# USB0_COMMON_0_VBP2APB_WRAP_CONTROLLER_VBP_CORE_ADDR_MAP register map
Vendor: Texas Instruments
Registers are 32-bit, access per field, reset 0x0 unless marked. A register's access mark holds for its fields unless they carry their own. Offsets are as the file gives them; [hi:lo] are bit positions; {n}, {i} and the like mark numbered series.

## USB0_COMMON_0_VBP2APB_WRAP_CONTROLLER_VBP_CORE_ADDR_MAP (part 4 of 8)
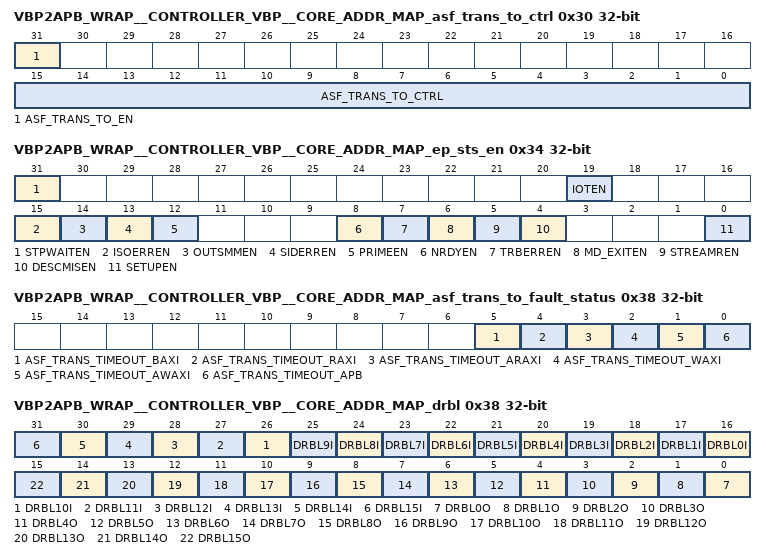
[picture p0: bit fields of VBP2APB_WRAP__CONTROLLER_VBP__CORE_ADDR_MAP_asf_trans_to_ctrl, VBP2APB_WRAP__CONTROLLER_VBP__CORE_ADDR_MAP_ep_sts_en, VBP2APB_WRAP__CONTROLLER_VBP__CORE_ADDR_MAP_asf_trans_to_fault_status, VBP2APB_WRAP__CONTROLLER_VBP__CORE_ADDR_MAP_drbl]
0x30 VBP2APB_WRAP__CONTROLLER_VBP__CORE_ADDR_MAP_asf_trans_to_ctrl
  [31] ASF_TRANS_TO_EN rw — Enable transaction timeout monitoring.
  [15:0] ASF_TRANS_TO_CTRL rw — Timer value to use for transaction timeout monitor.
0x30 VBP2APB_WRAP__CONTROLLER_VBP__CORE_ADDR_MAP_ep_sts_sid ro
  [15:0] SID — Stream ID [used only in SS mode]. Stream ID of packet, which generates interrupt. The interrupts that update the SID field are: - SIDERR for EP OUT - SIDERR/DESCMIS for EP IN For the above interrupts, the values of the SID field reflects: - in case of SIDERR for EP OUT this field reflects the Stream ID of OUT packet sent by host which was rejected by the device, due to SID_CHK bit set - in case of SIDERR/DESCMIS for EP IN this field reflects the Stream ID of ACK TP sent by host which was rejected by the device.
0x34 VBP2APB_WRAP__CONTROLLER_VBP__CORE_ADDR_MAP_asf_trans_to_fault_mask rw reset 0xFFFFFFFF
  [31:0] ASF_TRANS_TO_FAULT_MASK — Mask register for each ASF transaction timeout fault source.
0x34 VBP2APB_WRAP__CONTROLLER_VBP__CORE_ADDR_MAP_ep_sts_en
  [31] STPWAITEN rw — Setup Wait interrupt enable. This bit enables the STPWAIT interrupt. Valid only for EP0
  [19] IOTEN rw — Interrupt on Transmission complete enable. This bit enables the IOT interrupt.
  [15] ISOERREN rw — ISO transmission error enable. This bit enables the ISOERR interrupt.
  [14] OUTSMMEN rw — OUT size mismatch enable. This bit enables the OUTSMM interrupt.
  [13] SIDERREN rw — Stream error enable. This bit enables the SIDERR interrupt.
  [12] PRIMEEN rw — Prime enable. This bit enables the PRIME interrupt.
  [8] NRDYEN rw — NRDY enable. This bit enables the NRDY interrupt.
  [7] TRBERREN rw — TRB enable. This bit enables the TRBERR interrupt.
  [6] MD_EXITEN rw — Move Data Exit enable. This bit enables the MD_EXIT interrupt.
  [5] STREAMREN rw — Stream Rejected enable. This bit enables the STREAMR interrupt.
  [4] DESCMISEN rw — OUT transfer missing descriptor enable. This bit enables the DESCMIS interrupt.
  [0] SETUPEN rw — Setup transfer complete. This bit enables the SETUP interrupt. Valid only for EP0.
0x38 VBP2APB_WRAP__CONTROLLER_VBP__CORE_ADDR_MAP_asf_trans_to_fault_status access not given
  [5] ASF_TRANS_TIMEOUT_BAXI — Status bits for transaction timeouts faults - AXI Timeout [BAXI] (access R/W1TC)
  [4] ASF_TRANS_TIMEOUT_RAXI — Status bits for transaction timeouts faults - AXI Timeout [RAXI] (access R/W1TC)
  [3] ASF_TRANS_TIMEOUT_ARAXI — Status bits for transaction timeouts faults - AXI Timeout [ARAXI] (access R/W1TC)
  [2] ASF_TRANS_TIMEOUT_WAXI — Status bits for transaction timeouts faults - AXI Timeout [WAXI] (access R/W1TC)
  [1] ASF_TRANS_TIMEOUT_AWAXI — Status bits for transaction timeouts faults - AXI Timeout [AWAXI] (access R/W1TC)
  [0] ASF_TRANS_TIMEOUT_APB — Status bit for transaction timeout faults - APB timeout. (access R/W1TC)
0x38 VBP2APB_WRAP__CONTROLLER_VBP__CORE_ADDR_MAP_drbl access not given
  [n+16] DRBL{n}I (n=0..15) — Dorbel Bit - used for initiating transfers for selected Endpoint (access R/W1TS)
  [n] DRBL{n}O (n=0..15) — Dorbel Bit - used for initiating transfers for selected Endpoint (access R/W1TS)
0x3C VBP2APB_WRAP__CONTROLLER_VBP__CORE_ADDR_MAP_RSVD_16_ASF ro
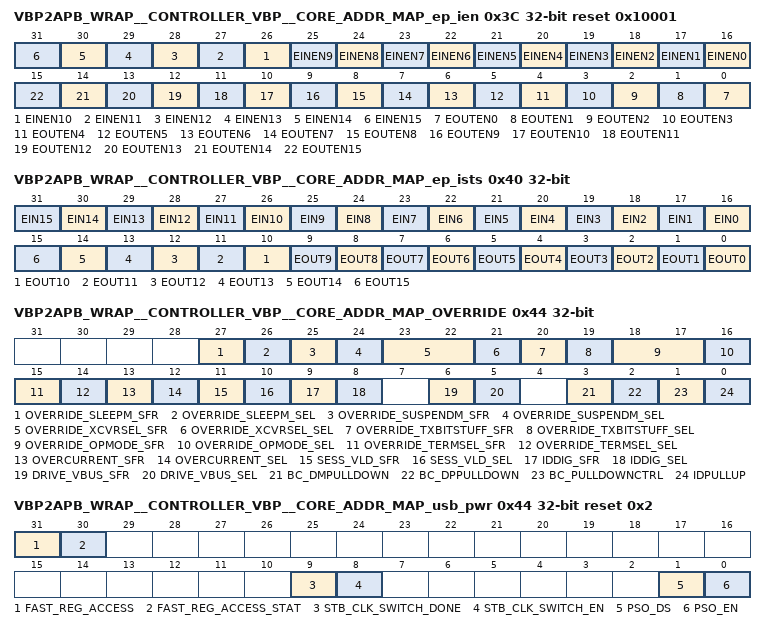
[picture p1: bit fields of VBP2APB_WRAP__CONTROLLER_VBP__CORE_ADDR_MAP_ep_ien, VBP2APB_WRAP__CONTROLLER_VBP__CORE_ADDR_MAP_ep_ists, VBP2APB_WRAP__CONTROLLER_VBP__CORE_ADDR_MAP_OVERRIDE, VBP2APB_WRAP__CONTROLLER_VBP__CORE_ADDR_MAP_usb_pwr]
0x3C VBP2APB_WRAP__CONTROLLER_VBP__CORE_ADDR_MAP_ep_ien rw reset 0x10001
  [n+16] EINEN{n} (n=0..15) — Endpoints Interrupt Enable Bit [1 - enables interrupt, 0 - disables interrupt]
  [n] EOUTEN{n} (n=0..15) — Endpoints Interrupt Enable Bit [1 - enables interrupt, 0 - disables interrupt]
0x40 VBP2APB_WRAP__CONTROLLER_VBP__CORE_ADDR_MAP_OTGSIMULATE
  [0] OTG_CFG_FAST_SIMS rw — Debug Feature. This bit is for simulation modes only. It enables reductions to OTG timings. '0': Normal timings '1': Enable fast simulation timing modes This bit should be written '0' in normal operation
0x40 VBP2APB_WRAP__CONTROLLER_VBP__CORE_ADDR_MAP_RSVD_17_ASF ro
0x40 VBP2APB_WRAP__CONTROLLER_VBP__CORE_ADDR_MAP_ep_ists ro
  [n+16] EIN{n} (n=0..15) — Endpoints Interrupt Status Bit.
  [n] EOUT{n} (n=0..15) — Endpoints Interrupt Status Bit.
0x44 VBP2APB_WRAP__CONTROLLER_VBP__CORE_ADDR_MAP_OVERRIDE
  [27] OVERRIDE_SLEEPM_SFR rw — SFR sleepm control. Value this bit is passed to PHY sleepm signal. This bit is valid only with PORT_OVERRIDE. override_sleepm_sel set to '1'.
  [26] OVERRIDE_SLEEPM_SEL rw — sleepm override select. This register allows SW driver override sleepm pin as follows: 0: sleepm is controlled from active controller [host/device/none] 1: sleepm controlled from SFR
  [25] OVERRIDE_SUSPENDM_SFR rw — SFR suspendm control. Value this bit is passed to PHY suspendm signal. This bit is valid only with PORT_OVERRIDE. override_suspendm_sel set to '1'.
  [24] OVERRIDE_SUSPENDM_SEL rw — suspendm override select. This register allows SW driver override suspendm pin as follows: 0: suspendm is controlled from active controller [host/device/none] 1: suspendm controlled from SFR
  [23:22] OVERRIDE_XCVRSEL_SFR rw — SFR xcvrselect control. Value of these bits is passed to PHY xcvrselect signal. This bit is valid only with PORT_OVERRRIDE. override_opmode_sel set to 1
  [21] OVERRIDE_XCVRSEL_SEL rw — xcvrselect override select. This register allows SW driver override xcvrselect pin as follows: 0: xcvrselect is controlled from active controller [host/device] 1: xcvrselect controlled from SFR
  [20] OVERRIDE_TXBITSTUFF_SFR rw — SFR txbitstuffenable control. Value this bit is passed to PHY txbitstuffenable signal. This bit is valid only with PORT_OVERRRIDE. override_txbitstuff_sel set to 1.
  [19] OVERRIDE_TXBITSTUFF_SEL rw — txbitstuffenable override select. This register allows SW driver override txbitstuffenable pin as follows: 0: txbitstuffenable is controlled from active controller [host/device] 1: txbitstuffenable controlled from SFR
  [18:17] OVERRIDE_OPMODE_SFR rw — SFR opmode control. Value these bits is passed to PHY opmode signal. This bit is valid only with PORT_OVERRRIDE. override_opmode_sel set to 1.
  [16] OVERRIDE_OPMODE_SEL rw — opmode override select. This register allows SW driver override opmode pin as follows: 0: opmode is controlled from active controller [host/device] 1: opmode controlled from SFR
  [15] OVERRIDE_TERMSEL_SFR rw — SFR overcurrent control. 0: overcurrent = 0 1: overcurrent = 1 This bit is valid only with PORT_OVERRRIDE.overcurrent_sel set to '1'. Note: overcurrent active state is low.
  [14] OVERRIDE_TERMSEL_SEL rw — termselect override select. This register allows SW driver override termselect pin as follows: 0: txbitstuffenable is controlled from active controller [host/device] 1: txbitstuffenable controlled from SFR
  [13] OVERCURRENT_SFR rw — SFR termselect control. Value this bit is passed to PHY termselect signal. This bit is valid only with PORT_OVERRRIDE. override_termsel_sel set to 1.
  [12] OVERCURRENT_SEL rw — Overcurrent override select This register allows SW driver override overcurrent pin as follows: 0: overcurrent is controlled from external FAULT detector 1: overcurrent controlled from SFR
  [11] SESS_VLD_SFR rw — SFR Vbusvalid/Sessvalid control. 0: Vbusvalid/Sessvalid = 0 1: Vbusvalid/Sessvalid = 1 This bit is valid only with PORT_OVERRRIDE.sess_vld_sel set to '1'.
  [10] SESS_VLD_SEL rw — Vbusvalid/Sessvalid override select. This register allows SW driver override Vbusvalid/Sessvalid pins as follows: 0: Vbusvalid/Sessvalid are controlled from OTG PHY 1: Vbusvalid/Sessvalid are controlled from SFR
  [9] IDDIG_SFR rw — SFR iddig control. 0: iddig = 0 1: iddig = 1 This bit is valid only with PORT_OVERRRIDE.iddig_sel set to '1'.
  [8] IDDIG_SEL rw — IDDIG override select. This register allows SW driver override iddig pin as follows: 0: iddig is controlled from OTG PHY 1: iddig controlled from SFR
  [6] DRIVE_VBUS_SFR rw — 0: drive_vbus = 0 1: drive_vbus = 1 This bit is valid only with USB2_PORT_OVERRRIDE.drive_vbus_sel set to '1'. This bit is auto-cleared upon over-current condition. Over-current doesn't disable vbus forcing.
  [5] DRIVE_VBUS_SEL rw — This register allows SW driver take control over drive_vbus as follows: 0: drive_vbus controlled from OTG controller 1: drive_vbus controlled from SFR
  [3] BC_DMPULLDOWN rw — dmpulldown enable This bit is valid only with PORT_OVERRRIDE.pulldownctrl_sel set to 1
  [2] BC_DPPULLDOWN rw — BC dppulldown enable This bit is valid only with PORT_OVERRRIDE.pulldownctrl_sel set to 1
  [1] BC_PULLDOWNCTRL rw — pulldowncotrol 1: puldowns are controlled by dppulldown_sfr and dmpulldown_sfr 0: puldowns are controlled by OTG
  [0] IDPULLUP rw — ID Pin Sample Enable: Active High. Signal that enables the sampling of the analog ID line. 0: Sampling of ID pin is disabled, iddig is not valid 1: Sampling of ID pin is enabled
0x44 VBP2APB_WRAP__CONTROLLER_VBP__CORE_ADDR_MAP_RSVD_18_ASF ro
0x44 VBP2APB_WRAP__CONTROLLER_VBP__CORE_ADDR_MAP_usb_pwr access not given reset 0x2
  [31] FAST_REG_ACCESS rw — Fast Registers Access. When Device Port is in a low power state [U3/L2/Not Connected], accesses to registers listed in section 2.3 of USBSS-DEV design specification may take long time. In order to enable fast register access in that case, user can use this register in the following way: - set FAST_REG_ACCESS bit - wait until FAST_REG_ACCESS_STAT bit is set - perform required accesses - clear FAST_REG_ACCESS bit Note that to enable USBSS-DEV low power state entry [U3/L2], the FAST_REG_ACCESS bit has to be cleared.
  [30] FAST_REG_ACCESS_STAT ro — Fast Registers Access status. This bit informs if Fast Registers Access is enabled. It should be used as described in FAST_REG_ACCESS bit.
  [9] STB_CLK_SWITCH_DONE ro — Status bit indicating that operation required by STB_CLK_SWITCH_EN write is completed. This bit is optional and implemented only when support for OTG is implemented [indicated by OTG_READY bit set to 1].
  [8] STB_CLK_SWITCH_EN rw — Enables turning-off Reference Clock. This bit is optional and implemented only when support for OTG is implemented [indicated by OTG_READY bit set to 1]. Should not be used when PHY Reference clock control is not supported
  [1] PSO_DS — Power Shut Off capability disable. Writing '1' to this bit disables power domains switching capability and clears the PSO_EN bit. It is recommended to set this bit after during U3EXTI interrupt service. (access R/W1TS)
  [0] PSO_EN — Power Shut Off capability enable. Writing '1' to this bit enables dower domains switching capability and clears the PSO_DS bit. The Domain will be switched off if both PSO_EN will be set and the USB controller will be in the in the U3 state. It is recommended to set this bit in U3ENTI interrupt service, after software ensures that no data transfer is pending. If this bit will be always set, the controller will automatically switch off the power in the switchable PD after USB controller will enter U3 state. (access R/W1TC)
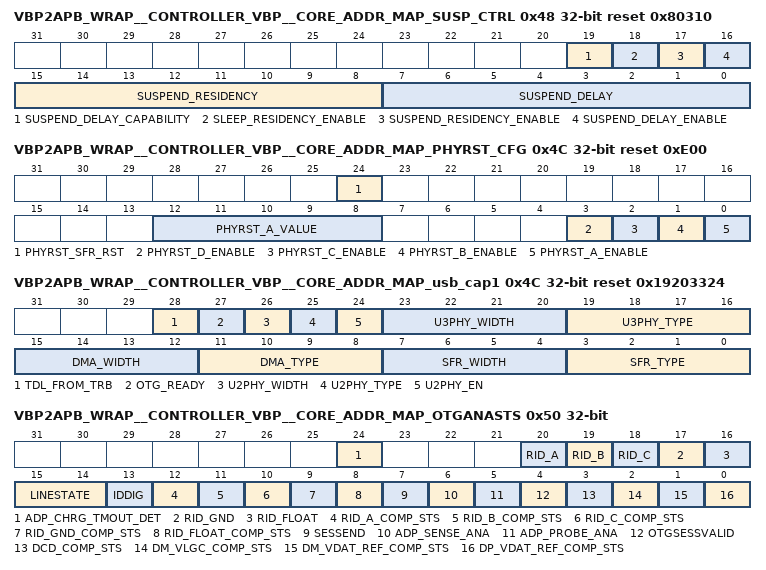
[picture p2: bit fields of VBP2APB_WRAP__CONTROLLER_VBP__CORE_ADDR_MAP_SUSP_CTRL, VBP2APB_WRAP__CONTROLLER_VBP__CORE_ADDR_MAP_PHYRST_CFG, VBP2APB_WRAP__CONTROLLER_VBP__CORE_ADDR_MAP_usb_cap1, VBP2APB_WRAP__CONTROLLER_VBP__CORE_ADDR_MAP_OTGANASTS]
0x48 VBP2APB_WRAP__CONTROLLER_VBP__CORE_ADDR_MAP_SUSP_CTRL reset 0x80310
  [19] SUSPEND_DELAY_CAPABILITY ro — Suspend delay capability. This is a configuration only field, therefore it can be changed by Software only during configuration phase when Power-On Reset [pwrup_rst_n] is asserted.
  [18] SLEEP_RESIDENCY_ENABLE rw — sleep minimum residency enable. This is a configuration only field, therefore it can be changed by Software only during configuration phase when Power-On Reset [pwrup_rst_n] is asserted.
  [17] SUSPEND_RESIDENCY_ENABLE rw — suspend minimum residency enable. This is a configuration only field, therefore it can be changed by Software only during configuration phase when Power-On Reset [pwrup_rst_n] is asserted.
  [16] SUSPEND_DELAY_ENABLE rw — suspend delay enable. This is a configuration only field, therefore it can be changed by Software only during configuration phase when Power-On Reset [pwrup_rst_n] is asserted.
  [15:8] SUSPEND_RESIDENCY rw — Suspend/Sleep minimum residency time [us]. This is a configuration only field, therefore it can be changed by Software only during configuration phase when Power-On Reset [pwrup_rst_n] is asserted.
  [7:0] SUSPEND_DELAY rw — Suspend assertion delay time [us]. This is a configuration only field, therefore it can be changed by Software only during configuration phase when Power-On Reset [pwrup_rst_n] is asserted.
0x48 VBP2APB_WRAP__CONTROLLER_VBP__CORE_ADDR_MAP_usb_conf2
  [0] AHB_RETRY_EN rw — AHB retry enable. This bit enables the AHB retrys for AHB slave interface. This bit has no effect when AHB slave interface is not implemented.
0x4C VBP2APB_WRAP__CONTROLLER_VBP__CORE_ADDR_MAP_PHYRST_CFG reset 0xE00
  [24] PHYRST_SFR_RST rw — Software USB20 PHy reset: 0 - SW utmi_reset not asserted 1 - SW utmi_reset asserted
  [12:8] PHYRST_A_VALUE rw — phyrst_a Rx fail timeout value. Value of this register is used as a timeout value for detecting Rx fail [utmi_rxactive is not up during Rx] Value of this register represent maximum number of UTMI clock cycles where utmi_rxactive is expected to rise with respect to Rx start judged by non-idle state utmi_linestate
  [3] PHYRST_D_ENABLE rw — Reset PHY after each utmi_opmode change from 2'b10 to any other value: 0 - disabled 1 - enabled
  [2] PHYRST_C_ENABLE rw — Reset PHY after each utmi_opmode change from 2'b01 to any other value: 0 - disabled 1 - enabled
  [1] PHYRST_B_ENABLE rw — Reset PHY after each transmitted packet in High-Speed: 0 - disabled 1 - enabled
  [0] PHYRST_A_ENABLE rw — Reset PHY if Rx fail is detected: 0 - disabled 1 - enabled
0x4C VBP2APB_WRAP__CONTROLLER_VBP__CORE_ADDR_MAP_usb_cap1 ro reset 0x19203324
  [28] TDL_FROM_TRB — This field informs if device controller supports automatic internal TDL calculation basing on the size provided in TRB for DMULT mode: - 0 - controller doesn't support automatic internal TDL calculation - 1 - controller supports automatic internal TDL calculation
  [27] OTG_READY — This field informs if device is OTG ready: - pure device mode: 0x0, - some features and ports for CDNS USB OTG controller are implemented: 0x1.
  [26] U2PHY_WIDTH — USB2 PHY Interface width. This field reflects width of USB2 PHY interface implemented: - 8 bit interface: 0x0, - 16 bit interface: 0x1. Note: The ULPI interface is always 8-bit wide.
  [25] U2PHY_TYPE — USB2 PHY Interface type. This field reflects type of USB2 PHY interface implemented: - UTMI: 0x0, - ULPI: 0x1.
  [24] U2PHY_EN — USB2 PHY Interface enable. This field informs if USB2 PHY interface is implemented: - interface NOT implemented: 0x0, - interface implemented: 0x1.
  [23:20] U3PHY_WIDTH — USB3 PHY Interface width. This field reflects width of USB3 PHY interface implemented: - 0x0: 8 bit PIPE interface, - 0x1: 16 bit PIPE interface, - 0x2: 32 bit PIPE interface, - 0x3: 64 bit PIPE interface, - 0x4-0xF: reserved. Note: When SSIC interface is implemented this field shows the width of internal PIPE interface. The RMMI interface is always 20-bit wide.
  [19:16] U3PHY_TYPE — USB3 PHY Interface type. This field reflects type of USB3 PHY interface implemented: - 0x0: USB PIPE, - 0x1: RMMI, - 0x2-0xF: reserved
  [15:12] DMA_WIDTH — DMA Interface width. This field reflects width of DMA interface implemented: - 0x0: reserved, - 0x1: reserved, - 0x2: 32 bit interface, - 0x3: 64 bit interface, - 0x4-0xF: reserved
  [11:8] DMA_TYPE — DMA Interface type. This field reflects type of DMA interface implemented: - 0x0: OCP, - 0x1: AHB, - 0x2: PLB, - 0x3: AXI, - 0x4-0xF: reserved
  [7:4] SFR_WIDTH — SFR Interface width. This field reflects width of SFR interface implemented: - 0x0: 8 bit interface, - 0x1: 16 bit interface, - 0x2: 32 bit interface, - 0x3: 64 bit interface, - 0x4-0xF: reserved
  [3:0] SFR_TYPE — SFR Interface type. This field reflects type of SFR interface implemented: 0x0 - OCP, 0x1 - AHB, 0x2 - PLB, 0x3 - AXI, 0x4 - APB, 0x5-0xF - reserved.
0x50 VBP2APB_WRAP__CONTROLLER_VBP__CORE_ADDR_MAP_OTGANASTS ro
  [24] ADP_CHRG_TMOUT_DET — ADP charge timeout detected
  [20] RID_A — RID A status reg
  [19] RID_B — RID B status reg
  [18] RID_C — RID C status reg
  [17] RID_GND — RID GND status reg
  [16] RID_FLOAT — RID float status reg
  [15:14] LINESTATE — Line State: These signals reflect the current state of the single ended receivers. They are combinatorial until a 'usable' sieclock is available, then they are synchronized to sieclock. They reflect the current state of the DP [linestate [0]] and DM [linestate [1]] signals. 00: SE0 [Single Ended Zero] 01: 'J' State 10: 'K' State 11: SE1 [Single Ended One]
  [13] IDDIG — ID Pin Status: Indicates whether the connected USB plug is Micro-A or Micro-B. This is only valid when idpullup is set to '1'. It must be valid within 50ms after idpullup is set to '1'. 0: Connected plug is a Micro-A 1: Connected plug is a Micro-B
  [12] RID_A_COMP_STS — RID A comparator status 1: RID_A Detected on ID Pin 0: RID_A not Detected on ID Pin
  [11] RID_B_COMP_STS — RID B comparator status 1: RID_B Detected on ID Pin 0: RID_B not Detected on ID Pin
  [10] RID_C_COMP_STS — RID C comparator status 1: RID_C Detected on ID Pin 0: RID_C not Detected on ID Pin
  [9] RID_GND_COMP_STS — RID GND comparator status 1: RID_GND Detected on ID Pin 0: RID_GND not Detected on ID Pin
  [8] RID_FLOAT_COMP_STS — RID float comparator status 1: RID_FLOAT Detected on ID Pin 0: RID_FLOAT not Detected on ID Pin
  [7] SESSEND — VBUS Valid: Indicates if the voltage on VBUS is at a valid level for operation [4.4V less than VTH less than 4.75V]. 0: VBUS less than 4.4V 1: VBUS > 4.75V
  [6] ADP_SENSE_ANA — Output of ADP Sense Comparator. 0: VBUS less than 0.2V 1: VBUS > 0.55V
  [5] ADP_PROBE_ANA — Output of ADP Probe Comparator. 0: VBUS less than 0.6V 1: VBUS > 0.75V
  [4] OTGSESSVALID — B-Peripheral is Valid: Indicates if the session for a B-Peripheral is valid [0.8V less than VTH less than 4.0V]. The signal bvalid from OTG 1.3 is now renamed as otgsessvalid. 0: VBUS less than 0.8V 1: VBUS > 4.0V
  [3] DCD_COMP_STS — Data Contact Detect [DCD] Comparator Status 1: DP line is asserted 0: DP line is not asserted
  [2] DM_VLGC_COMP_STS — 1: DM > VLGC Detected 0: DM less than VLGC Detected Note: This status shall be re-used from the single ended receiver output of D- whenever dm_vlgc_comp_en is '1'.
  [1] DM_VDAT_REF_COMP_STS — 1: DM > VDAT_REF Detected 0: DM less than VDAT_REF Detected Note: This status shall be re-used from the single ended receiver output of D- whenever dm_vdat_ref_comp_en is '1'.
  [0] DP_VDAT_REF_COMP_STS — 1: DP > VDAT_REF Detected 0: DP less than VDAT_REF Detected Note: This status shall be re-used from the single ended receiver output of D+ whenever dp_vdat_ref_comp_en is '1'.
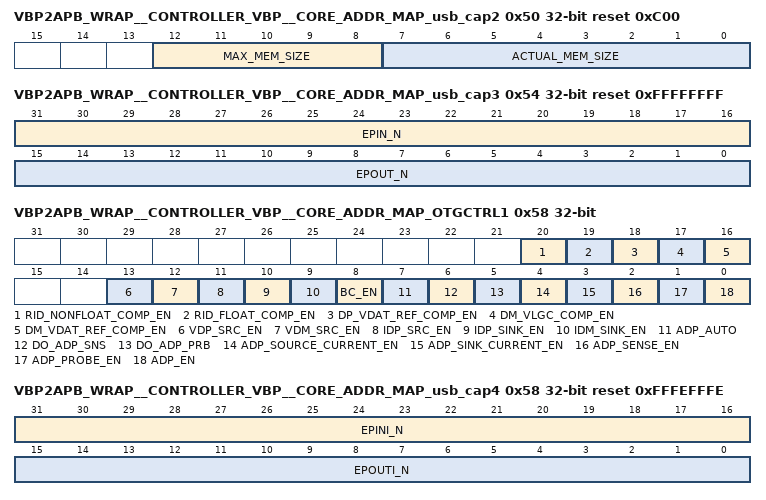
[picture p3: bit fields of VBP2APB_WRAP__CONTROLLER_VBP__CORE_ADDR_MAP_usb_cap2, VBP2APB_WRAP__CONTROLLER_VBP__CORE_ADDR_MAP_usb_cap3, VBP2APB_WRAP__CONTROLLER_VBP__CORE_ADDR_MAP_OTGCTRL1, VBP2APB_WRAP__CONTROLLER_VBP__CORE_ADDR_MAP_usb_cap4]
0x50 VBP2APB_WRAP__CONTROLLER_VBP__CORE_ADDR_MAP_usb_cap2 ro reset 0xC00
  [12:8] MAX_MEM_SIZE — Max supported mem size. This field reflects width of on-chip RAM address bus width, which determines max supported mem size: 0x0-0x7 reserved, 0x8 - support for 4kB mem, 0x9 - support for 8kB mem, 0xA - support for 16kB mem, 0xB - support for 32kB mem, 0xC - support for 64kB mem, 0xD - support for 128kB mem, 0xE - support for 256kB mem, 0xF - reserved.
  [7:0] ACTUAL_MEM_SIZE — The actual size of the connected On-chip RAM memory in kB: - 0 means 256 kB [max supported mem size] - value other than 0 reflects the mem size in kB. This value reflects the CDNS_USBSSDEV_ATTACHED_MEM_SIZE parameter defined in the usbss_dev_defines.v file. This value has to be adequately set before synthesis by engineer who connects the on-chip memory for controller.
0x54 VBP2APB_WRAP__CONTROLLER_VBP__CORE_ADDR_MAP_ADP_RAMP_TIME ro
  [31:0] ADP_RAMP_TIME — ADP ramp time measurement value. Software should read this register upon ADP_PROBE_COMPLETED_INT_EN interrupt detection
0x54 VBP2APB_WRAP__CONTROLLER_VBP__CORE_ADDR_MAP_usb_cap3 ro reset 0xFFFFFFFF
  [31:16] EPIN_N — Endpoints IN
  [15:0] EPOUT_N — Endpoints OUT
0x58 VBP2APB_WRAP__CONTROLLER_VBP__CORE_ADDR_MAP_OTGCTRL1
  [20] RID_NONFLOAT_COMP_EN rw — 1: RID Non-Float Comparator Enabled 0: RID Non-Float Comparator Disabled Note: This ID Comparator enable is used to detect the presence of RID_A or RID_B or RID_C or RID_GND when the ID pin is non-floating.
  [19] RID_FLOAT_COMP_EN rw — 1: RID Float Comparator Enabled 0: RID Float Comparator Disabled Note: This ID Comparator enable is used to detect whether the ID line is floating or non-floating. If it is identified to be non-floating, then rid_nonfloat_comp_en is enabled to check for RID_A or RID_B or RID_C or RID_GND.
  [18] DP_VDAT_REF_COMP_EN rw — 1: DP to VDAT_REF Comparator Enabled 0: DP to VDAT_REF Comparator Disabled
  [17] DM_VLGC_COMP_EN rw — 1: DM to VLGC Comparator Enabled 0: DM to VLGC Comparator Disabled
  [16] DM_VDAT_REF_COMP_EN rw — 1: DM to VDAT_REF Comparator Enabled 0: DM to VDAT_REF Comparator Disabled
  [13] VDP_SRC_EN rw — 1: Voltage Source on DP Enabled 0: Voltage Source on DP Disabled
  [12] VDM_SRC_EN rw — 1: Voltage Source on DM Enabled 0: Voltage Source on DM Disabled
  [11] IDP_SRC_EN rw — 1: Current Source on DP Enabled 0: Current Source on DP Disabled
  [10] IDP_SINK_EN rw — 1: Current Sink on DP Enabled 0: Current Sink on DP Disabled
  [9] IDM_SINK_EN rw — 1: Current Sink on DM Enabled 0: Current Sink on DM Disabled
  [8] BC_EN rw — Battery Charging Circuits Master Enable. 1: BC Enabled 0: BC Disabled
  [7] ADP_AUTO rw — ADP mode. If set to 1 ADP probing is controlled by internal FSM. If set to 0 then software should control ADP sequence.
  [6] DO_ADP_SNS rw — ADP sensing enable in automated mode
  [5] DO_ADP_PRB rw — ADP probing enable in automated mode
  [4] ADP_SOURCE_CURRENT_EN rw — When this signal is high, VBUS is charged to the probe threshold [0.75V]. This signal should be asserted 5us after the assertion of adp_en. 0: ADP Source Current Enable OFF 1: ADP Source Current Enable ON
  [3] ADP_SINK_CURRENT_EN rw — When this signal is high, VBUS is discharged to ground. This signal should be asserted 5us after the assertion of adp_en. 0: ADP Sink Current Enable OFF 1: ADP Sink Current Enable ON
  [2] ADP_SENSE_EN rw — This signal enables the probe mode of the ADP. During this mode, sense comparators and the current sources will be ON based on the source and sink current enables. 0: ADP Probe Sense OFF 1: ADP Probe Sense ON
  [1] ADP_PROBE_EN rw — This signal enables the probe mode of the ADP. During this mode, probe comparators and the current sources will be ON based on the source and sink current enables. 0: ADP Probe Mode OFF 1: ADP Probe Mode ON
  [0] ADP_EN rw — ADP Feature Enable. This signal is the master enable for all the ADP PHY logics. 0: ADP Logics are powered OFF 1: ADP Logics are powered ON
0x58 VBP2APB_WRAP__CONTROLLER_VBP__CORE_ADDR_MAP_usb_cap4 ro reset 0xFFFEFFFE
  [31:16] EPINI_N — Endpoints IN
  [15:0] EPOUTI_N — Endpoints OUT
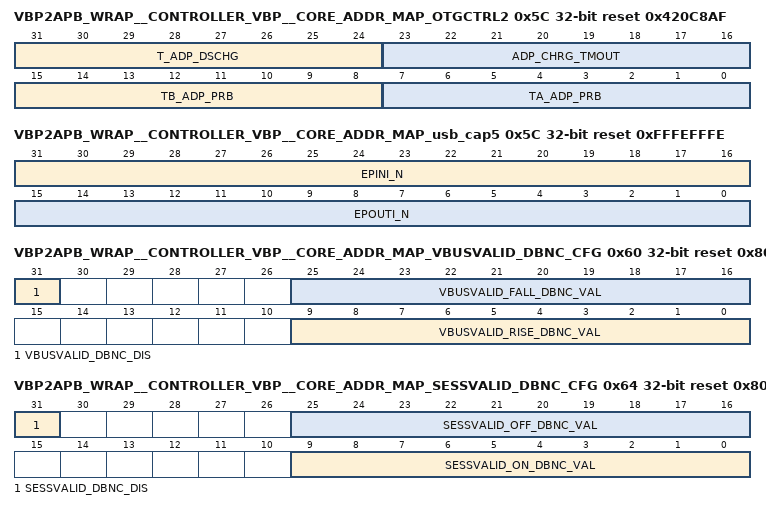
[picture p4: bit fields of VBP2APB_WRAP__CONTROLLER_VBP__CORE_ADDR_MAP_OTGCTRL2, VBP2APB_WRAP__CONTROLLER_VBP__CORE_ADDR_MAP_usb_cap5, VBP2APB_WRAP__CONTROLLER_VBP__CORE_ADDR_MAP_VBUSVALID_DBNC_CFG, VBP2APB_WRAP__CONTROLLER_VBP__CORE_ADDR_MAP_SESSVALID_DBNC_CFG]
0x5C VBP2APB_WRAP__CONTROLLER_VBP__CORE_ADDR_MAP_OTGCTRL2 rw reset 0x420C8AF
  [31:24] T_ADP_DSCHG — ADP probing discharge time. T_ADP_DSCHG = {reg_value} * 1 ms
  [23:16] ADP_CHRG_TMOUT — ADP probing timeout value. Defines maximum time for ADP charging. If this time is reached during charging then adp_chrg_tmout_det bit in OTGADPBCSTS is set ADP_CHRG_TMOUT = {reg_value} * 1 ms
  [15:8] TB_ADP_PRB — B-device ADP probing period. TB_ADP_PRB = {reg_value} * 10 ms
  [7:0] TA_ADP_PRB — A-device ADP probing period. TA_ADP_PRB = {reg_value} * 10 ms
0x5C VBP2APB_WRAP__CONTROLLER_VBP__CORE_ADDR_MAP_usb_cap5 ro reset 0xFFFEFFFE
  [31:16] EPINI_N — Endpoints IN
  [15:0] EPOUTI_N — Endpoints OUT
0x60 VBP2APB_WRAP__CONTROLLER_VBP__CORE_ADDR_MAP_VBUSVALID_DBNC_CFG reset 0x800A000A
  [31] VBUSVALID_DBNC_DIS rw — Vbusvalid debounce disable
  [25:16] VBUSVALID_FALL_DBNC_VAL rw — Vbusvalid off debounce: Debounce timer value = reg value x 100us
  [9:0] VBUSVALID_RISE_DBNC_VAL rw — Vbusvalid on debounce: Debounce timer value = reg value x 100us
0x60 VBP2APB_WRAP__CONTROLLER_VBP__CORE_ADDR_MAP_usb_cap6 ro reset 0x2450D
  [31:0] VERSION — Device controller version.
0x64 VBP2APB_WRAP__CONTROLLER_VBP__CORE_ADDR_MAP_SESSVALID_DBNC_CFG reset 0x800A0100
  [31] SESSVALID_DBNC_DIS rw — Sessvalid debounce disable
  [25:16] SESSVALID_OFF_DBNC_VAL rw — Sessvalid off debounce: Debounce timer value = reg value x 100us
  [9:0] SESSVALID_ON_DBNC_VAL rw — Sessvalid on debounce: Debounce timer value = reg value x 100us
{0x60+4i} VBP2APB_WRAP__CONTROLLER_VBP__CORE_ADDR_MAP_usb_cpkt{i} rw (i=1..3)
  [31:0] CPKT{i} — Custom Packet value {i}.
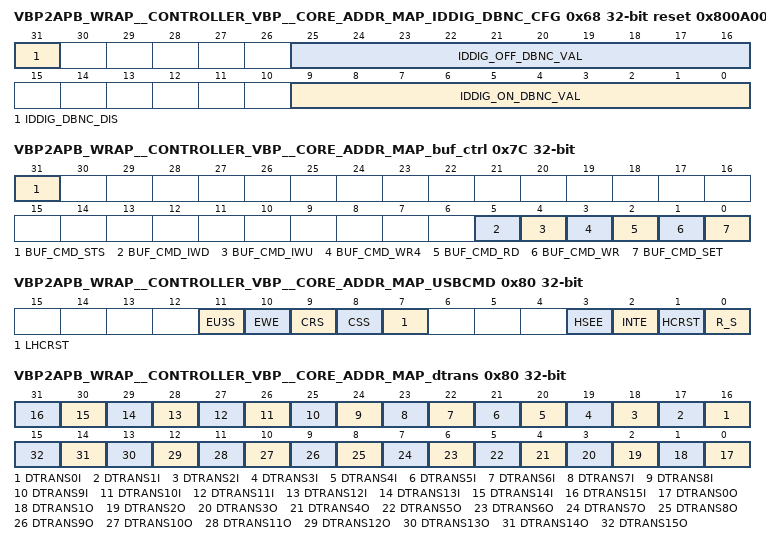
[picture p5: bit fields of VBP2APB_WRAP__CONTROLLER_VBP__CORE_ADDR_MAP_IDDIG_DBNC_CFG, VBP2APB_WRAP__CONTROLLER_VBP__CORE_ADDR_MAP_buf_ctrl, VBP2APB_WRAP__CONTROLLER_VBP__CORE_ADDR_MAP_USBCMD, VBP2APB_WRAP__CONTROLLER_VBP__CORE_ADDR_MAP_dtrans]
0x68 VBP2APB_WRAP__CONTROLLER_VBP__CORE_ADDR_MAP_IDDIG_DBNC_CFG reset 0x800A000A
  [31] IDDIG_DBNC_DIS rw — Iddig debounce disable
  [25:16] IDDIG_OFF_DBNC_VAL rw — Sessvalid off debounce: Debounce timer value = reg value x 100us
  [9:0] IDDIG_ON_DBNC_VAL rw — Sessvalid on debounce: Debounce timer value = reg value x 100us
0x70 VBP2APB_WRAP__CONTROLLER_VBP__CORE_ADDR_MAP_ep_dma_ext_addr
  [15:0] EP_DMA_ADDR_H rw — Transfer Ring address. This register specify upper [above 32-bits] DMA address for each endpoint separatelly. This part of DMA address, is not modified by the DMA. CPU can use this register [read it or write to it] only when endpoint is selected [using EP_SEL register]
0x74 VBP2APB_WRAP__CONTROLLER_VBP__CORE_ADDR_MAP_buf_addr rw
  [31:0] BUF_ADDR — On-chip Memory Address. This register specify the address of the on-chip memory cell which is accessed using BUF_CTRL register.
0x78 VBP2APB_WRAP__CONTROLLER_VBP__CORE_ADDR_MAP_buf_data rw
  [31:0] BUF_DATA — Data for On-chip Buffer operations. This register specify the address of the on-chip memory cell which is accessed using BUF_CTRL register. For write operation this register must be written before WRITE command is issued using BUF_CTRL register. For read operation, this register must be read after READ command is issued using BUF_CTRL register.
0x7C VBP2APB_WRAP__CONTROLLER_VBP__CORE_ADDR_MAP_buf_ctrl
  [31] BUF_CMD_STS ro — Status of BUF_CMD operations. This bit is set high when controller performs BUF CMD IWD and IWU operations. When it is set, no other SFR or DMA operation can be issued to the controller.
  [5] BUF_CMD_IWD rw — Incremental write counting down to device on-chip mem. Used for incremental writing data into device on-chip memory starting from address pointed by BUF_ADDR register [two lsb rounded down to 0]. To write data to memory, the following order must be maintained: 1] BUF_ADDR register must be set with start address, 2] The BUF_DATA must be set with data expected to be written to on-chip mem 3] BUF_CMD_IWD with BUF_CMD_SET must be set to perform write operation. This write operation is effective only when this BUF_CMD_IWD bit is set together with the BUF_CMD_SET bit. As long as controller performs this command, the BUF_CMD_STS status bit is set, and no other SFR or DMA operation can be issued to the controller. This command can be useful during memory initialization
  [4] BUF_CMD_IWU rw — Incremental write counting up to device on-chip mem. Used for incremental writing data into device on-chip memory starting from address pointed by BUF_ADDR register [two lsb rounded down to 0]. To write data to memory, the following order must be maintained: 1] BUF_ADDR register must be set with start address, 2] The BUF_DATA must be set with data expected to be written to on-chip mem 3] BUF_CMD_IWD with BUF_CMD_SET must be set to perform write operation. This write operation is effective only when this BUF_CMD_IWU bit is set together with the BUF_CMD_SET bit. As long as controller performs this command, the BUF_CMD_STS status bit is set, and no other SFR or DMA operation can be issued to the controller. This command can be useful during memory initialization
  [3] BUF_CMD_WR4 rw — Write 4 words [16B] to device on-chip mem. Used for writing 4 words [4x duplicated BUF_DATA data] into device on-chip memory at address pointed by BUF_ADDR register [two lsb rounded down to 0]. To write data to memory, the following order must be maintained: 1] BUF_ADDR register must be set with address to be accessed, 2] The BUF_DATA must be set with data expected to be written to on-chip mem 3] BUF_CMD_WR4 with BUF_CMD_SET must be set to perform write operation. During this operation the BUF_DATA [duplicated 4 times] register is written to memory. This write operation is effective only when this BUF_CMD_WR4 bit is set together with the BUF_CMD_SET bit. This command can be useful during memory initialization
  [2] BUF_CMD_RD rw — Read data [32B] from device on-chip mem. Used for reading data [1 word] from device on-chip memory from address pointed by BUF_ADDR register. To read data from memory,the following order must be maintained: 1] BUF_ADDR register must be set with address to be accessed, 2] BUF_CMD_RD with BUF_CMD_SET must be set to perform read operation. During this operation the BUF_DATA register is loaded with data readed from memory 3] The BUF_DATA can be read. This read operation is effective only when this BUF_CMD_RD bit is set together with the BUF_CMD_SET bit.
  [1] BUF_CMD_WR rw — Write 1 word [4B] to device on-chip mem. Used for writing 1 word [as prepared in BUF_DATA register] into device on-chip memory at address pointed by BUF_ADDR register. To write data to memory,the following order must be maintained: 1] BUF_ADDR register must be set with address to be accessed, 2] The BUF_DATA must be set with data expected to be written to on-chip mem 3] BUF_CMD_WR with BUF_CMD_SET must be set to perform write operation. During this operation the BUF_DATA register is written to memory. This write operation is effective only when this BUF_CMD_WR bit is set together with the BUF_CMD_SET bit.
  [0] BUF_CMD_SET rw — Buffer Command Set. This bit must be written 1 in conjuction with one of WR, RD, WR4 IWD or IWU commands to make command effective. Only one command can be set at a moment. Commands WR, WR4 and RD are executed immediatelly, but after issuing commands IWD and IWU, the BUF_CMD_STS bit must be check before going forward to other SW operations
0x80 VBP2APB_WRAP__CONTROLLER_VBP__CORE_ADDR_MAP_USBCMD
  [11] EU3S rw — Enable U3 MFINDEX Stop [EU3S], RW. Default = '0'. When set to '1', the xHC may stop the MFINDEX counting action if all Root Hub ports are in the U3, Disconnected, Disabled, or Powered-off state. When cleared to '0' the xHC may stop the MFINDEX counting action if all Root Hub ports are in the Disconnected, Disabled, Training, or Powered-off state. Refer to section 4.14.2 of xHCI specification for more information.
  [10] EWE rw — Enable Wrap Event [EWE], RW. Default = '0'. When set to '1', the xHC shall generate a MFINDEX Wrap Event every time the MFINDEX register transitions from 03FFFh to 0. When cleared to '0' no MFINDEX Wrap Events are generated. Refer to section 4.14.2 of xHCI specification for more information. When this register is exposed by a Virtual Function [VF], the generation of MFINDEX Wrap Events to VFs shall be emulated by the VMM.
  [9] CRS rw — Controller Restore State [CRS], RW. Default = '0'. When set to '1', and HCHalted [HCH] = '1', then the xHC shall perform a Restore State operation and restore its internal state. When set to '1' and Run/Stop [R/S] = '1' or HCHalted [HCH] = '0', or when cleared to '0', no Restore State operation shall be performed. This flag always returns '0' when read. Refer to the Restore State Status [RSS] flag in the USBSTS register for information on Restore State completion. Refer to section 4.23.2 of xHCI specification for more information. Note that undefined behavior may occur if a Restore State operation is initiated while Save State Status [SSS] = '1'. When this register is exposed by a Virtual Function [VF], this bit only controls restoring the state of the xHC instance presented by the selected VF. Refer to section 8 of xHCI specification for more information.
  [8] CSS rw — Controller Save State [CSS], RW. Default = '0'. When written by software with '1' and HCHalted [HCH] = '1', then the xHC shall save any internal state that may be restored by a subsequent Restore State operation. When written by software with '1' and HCHalted [HCH] = '0', or written with '0', no Save State operation shall be performed. This flag always returns '0' when read. Refer to the Save State Status [SSS] flag in the USBSTS register for information on Save State completion. Refer to section 4.23.2 of xHCI specification for more information on xHC Save/Restore operation. Note that undefined behavior may occur if a Save State operation is initiated while Restore State Status [RSS] ='1'. When this register is exposed by a Virtual Function [VF], this bit only controls saving the state of the xHC instance presented by the selected VF. Refer to section 8 of xHCI specifications for more information.
  [7] LHCRST ro — Light Host Controller Reset [LHCRST], RO or RW. Optional normative. Default = '0'. If the Light HC Reset Capability [LHRC] bit in the HCCPARAMS register is '1', then this flag allows the driver to reset the xHC without affecting the state of the ports. A system software read of this bit as '0' indicates the Light Host Controller Reset has completed and it is safe for software to re-initialize the xHC. A software read of this bit as a '1' indicates that the Light Host Controller Reset has not yet completed. If not implemented, a read of this flag shall always return a '0'. All registers in the Aux Power well shall maintain the values that had been asserted prior to the Light Host Controller Reset. Refer to section 4.23.1 of xHCI specification for more information. When this register is exposed by a Virtual Function [VF], this bit only generates a Light Reset to the xHC instance presented by the selected VF, e.g. Disable the VFs device slots and set the associated VF Run bit to Stopped. Refer to section 8 of xHCI specification for more information.
  [3] HSEE rw — Host System Error Enable [HSEE], RW. Default = '0'. When this bit is a '1', and the HSE bit in the USBSTS register is a '1', the xHC shall assert out-of-band error signaling to the host. The signaling is acknowledged by software clearing the HSE bit. Refer to section 4.10.2.6 of xHCI specification for more information. When this register is exposed by a Virtual Function [VF], the effect of the assertion of this bit on the Physical Function [PF0] is determined by the VMM. Refer to section 8 of xHCI specification for more information.
  [2] INTE rw — Interrupter Enable [INTE], RW. Default = '0'. This bit provides system software with a means of enabling or disabling the host system interrupts generated by Interrupters. When this bit is a '1', then Interrupter host system interrupt generation is allowed, e.g. the xHC shall issue an interrupt at the next interrupt threshold if the host system interrupt mechanism [e.g. MSI, MSIX, etc.] is enabled. The interrupt is acknowledged by a host system interrupt specific mechanism. When this register is exposed by a Virtual Function [VF], this bit only enables the set of Interrupters assigned to the selected VF. Refer to section 7.7.2 of xHCI specification for more information.
  [1] HCRST rw — Host Controller Reset [HCRST], RW. Default = '0'. This control bit is used by software to reset the host controller. The effects of this bit on the xHC and the Root Hub registers are similar to a Chip Hardware Reset. When software writes a '1' to this bit, the Host Controller resets its internal pipelines, timers, counters, state machines, etc. to their initial value. Any transaction currently in progress on the USB is immediately terminated. A USB reset shall not be driven on USB2 downstream ports, however a Hot or Warm Reset shall be initiated on USB3 Root Hub downstream ports. PCI Configuration registers are not affected by this reset. All operational registers, including port registers and port state machines are set to their initial values. Software shall reinitialize the host controller as described in Section 4.1 of xHCI specification in order to return the host controller to an operational state. This bit is cleared to '0' by the Host Controller when the reset process is complete. Software cannot terminate the reset process early by writing a '0' to this bit and shall not write any xHC Operational or Runtime registers until while HCRST is '1'. Note, the completion of the xHC reset process is not gated by the Root Hub port reset process. Software shall not set this bit to '1' when the HCHalted [HCH] bit in the USBSTS register is a '0'. Attempting to reset an actively running host controller may result in undefined behavior. When this register is exposed by a Virtual Function [VF], this bit only resets the xHC instance presented by the selected VF. Refer to section 8 of xHCI specification for more information.
  [0] R_S rw — Run/Stop [R/S], RW. Default = '0'. '1' = Run. '0' = Stop. When set to a '1', the xHC proceeds with execution of the schedule. The xHC continues execution as long as this bit is set to a '1'. When this bit is cleared to '0', the xHC completes any current or queued commands or TDs, and any USB transactions associated with them, then halts. Refer to section 5.4.1.1 of xHCI specification for more information on how R/S shall be managed. The xHC shall halt within 16 ms after software clears the Run/Stop bit if the above conditions have been met. The HCHalted [HCH] bit in the USBSTS register indicates when the xHC has finished its pending pipelined transactions and has entered the stopped state. Software shall not write a '1' to this flag unless the xHC is in the Halted state [i.e. HCH in the USBSTS register is '1']. Doing so may yield undefined results. Writing a '0' to this flag when the xHC is in the Running state [i.e. HCH = '0'] and any Event Rings are in the Event Ring Full state [refer to section 4.9.4 of xHCI specification] may result in lost events. When this register is exposed by a Virtual Function [VF], this bit only controls the run state of the xHC instance presented by the selected VF. Refer to section 8 of xHCI specification for more information.
0x80 VBP2APB_WRAP__CONTROLLER_VBP__CORE_ADDR_MAP_dtrans rw
  [n+16] DTRANS{n}I (n=0..15) — DMA transfer configuration status for selected Endpoint[0 - single request - Single TRB chain. Single request [DRDY/Doorbell] triggers DMA, which transfers single TRB chain only and ends the EP transfer. 1 - single request - Multiple TRB chain. Single request [DRDY/Doorbell] triggers DMA which starts transfer until the owner of the new chain is not DMA [this causes a TRB error interrupt]. ]
  [n] DTRANS{n}O (n=0..15) — DMA transfer configuration status for selected Endpoint[0 - single request - Single TRB chain. Single request [DRDY/Doorbell] triggers DMA, which transfers single TRB chain only and ends the EP transfer. 1 - single request - Multiple TRB chain. Single request [DRDY/Doorbell] triggers DMA which starts transfer until the owner of the new chain is not DMA [this causes a TRB error interrupt]. ]
